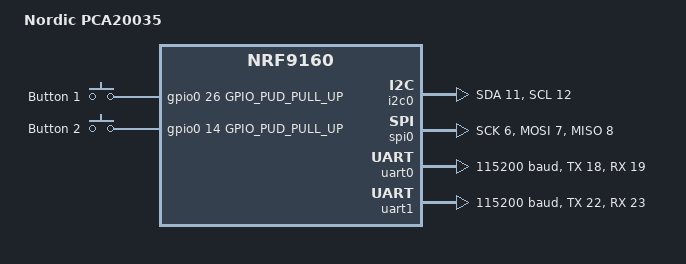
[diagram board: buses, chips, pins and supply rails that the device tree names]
/*
 * Copyright (c) 2017 Linaro Limited
 * Copyright (c) 2018 Nordic Semiconductor ASA
 *
 * SPDX-License-Identifier: Apache-2.0
 */

/dts-v1/;
#include <nordic/nrf9160_xxaa.dtsi>

/ {
	model = "Nordic PCA20035";
	compatible = "nordic,pca20035", "nordic,nrf9160-xxaa";

	chosen {
		zephyr,sram = &sram0;
		zephyr,flash = &flash0;
	};

	buttons {
		compatible = "gpio-keys";
		#address-cells = <1>;
		#size-cells = <0>;

		button0: button_0 {
			gpios = <&gpio0 26 GPIO_PUD_PULL_UP>;
			label = "Button 1";
		};

		button1: button_1 {
			gpios = <&gpio0 14 GPIO_PUD_PULL_UP>;
			label = "Button 2";
		};
	};

	aliases {
		sw0 = &button0;
		sw1 = &button1;
	};

	sram0_bsd: memory@20010000 {
		device_type = "memory";
		compatible = "mmio-sram";
	};
};

&gpiote {
	status = "ok";
};

&gpio0 {
	status = "ok";
};

&i2c0 {
	status = "ok";
	sda-pin = <11>;
	scl-pin = <12>;
};

&spi0 {
	status = "ok";
	sck-pin = <6>;
	mosi-pin = <7>;
	miso-pin = <8>;
};

&uart0 {
	current-speed = <115200>;
	status = "ok";
	tx-pin = <18>;
	rx-pin = <19>;
	rts-pin = <20>;
	cts-pin = <21>;
};

&uart1 {
	current-speed = <115200>;
	status = "ok";
	tx-pin = <22>;
	rx-pin = <23>;
	rts-pin = <24>;
	cts-pin = <25>;
};

&flash0 {
	/*
	 * For more information, see:
	 * http://docs.zephyrproject.org/devices/dts/flash_partitions.html
	 */
	partitions {
		compatible = "fixed-partitions";
		#address-cells = <1>;
		#size-cells = <1>;

		boot_partition: partition@0 {
			label = "mcuboot";
			reg = <0x00000000 0x10000>;
		};
		slot0_partition: partition@10000 {
			label = "image-0";
		};
#if defined(CONFIG_ARM_TRUSTZONE_M)
		slot0_ns_partition: partition@40000 {
			label = "image-0-nonsecure";
		};
#endif
		slot1_partition: partition@80000 {
			label = "image-1";
		};
#if defined(CONFIG_ARM_TRUSTZONE_M)
		slot1_ns_partition: partition@b0000 {
			label = "image-1-nonsecure";
		};
#endif
		scratch_partition: partition@f0000 {
			label = "image-scratch";
			reg = <0x000f0000 0xa000>;
		};

#if defined(CONFIG_FILE_SYSTEM_NFFS)
		nffs_partition: partition@fa000 {
			label = "nffs";
			reg = <0x000fa000 0x00006000>;
		};
#endif
	};
};

#if defined(CONFIG_ARM_TRUSTZONE_M)
/ {
	sram0_ns: memory@20020000 {
		device_type = "memory";
		compatible = "mmio-sram";
	};
};
#endif

/* Include partition configuration file */
#include "nrf9160_pca20035_partition_conf.dts"
